# ATSAMD21J17D register map
Vendor: Microchip Technology Inc.; File version: G
CPU: CM0+ r0p1, little endian, no MPU, no FPU, 0x2 interrupt priority bits, 0x0 interrupts
Registers are 32-bit, read-write, reset 0x0 unless marked. A register's access mark holds for its fields unless they carry their own. Offsets are from the block's base; [hi:lo] are bit positions; {n}, {i} and the like mark numbered series; 'fields as' and 'values as' point back to an identical list.

## PORT — Port Module
Base 0x41004400; register names take the prefix PORT_
0x00 DIR0 — Data Direction
  [31:0] DIR — Port Data Direction
0x04 DIRCLR0 — Data Direction Clear
  [31:0] DIRCLR — Port Data Direction Clear
0x08 DIRSET0 — Data Direction Set
  [31:0] DIRSET — Port Data Direction Set
0x0C DIRTGL0 — Data Direction Toggle
  [31:0] DIRTGL — Port Data Direction Toggle
0x10 OUT0 — Data Output Value
  [31:0] OUT — Port Data Output Value
0x14 OUTCLR0 — Data Output Value Clear
  [31:0] OUTCLR — Port Data Output Value Clear
0x18 OUTSET0 — Data Output Value Set
  [31:0] OUTSET — Port Data Output Value Set
0x1C OUTTGL0 — Data Output Value Toggle
  [31:0] OUTTGL — Port Data Output Value Toggle
0x20 IN0 ro — Data Input Value
  [31:0] IN — Port Data Input Value
0x24 CTRL0 — Control
  [31:0] SAMPLING wo — Input Sampling Mode
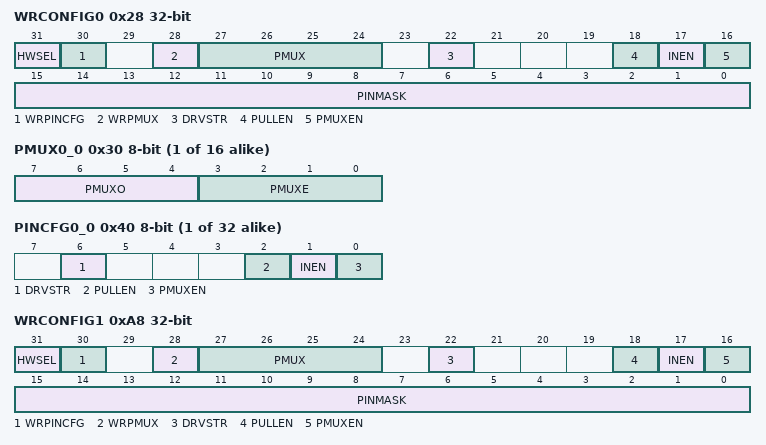
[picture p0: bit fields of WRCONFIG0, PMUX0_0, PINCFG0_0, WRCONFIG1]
0x28 WRCONFIG0 wo — Write Configuration
  [31] HWSEL — Half-Word Select
  [30] WRPINCFG — Write PINCFG
  [28] WRPMUX — Write PMUX
  [27:24] PMUX — Peripheral Multiplexing
  [22] DRVSTR — Output Driver Strength Selection
  [18] PULLEN — Pull Enable
  [17] INEN — Input Enable
  [16] PMUXEN — Peripheral Multiplexer Enable
  [15:0] PINMASK — Pin Mask for Multiple Pin Configuration
{0x30+i} PMUX0_{i} 8-bit (i=0..15) — Peripheral Multiplexing n - Group 0
  [7:4] PMUXO — Peripheral Multiplexing Odd
    0=A (Peripheral function A selected); 1=B (Peripheral function B selected); 2=C (Peripheral function C selected); 3=D (Peripheral function D selected); 4=E (Peripheral function E selected); 5=F (Peripheral function F selected); 6=G (Peripheral function G selected); 7=H (Peripheral function H selected)
  [3:0] PMUXE — Peripheral Multiplexing Even
    values as PMUXO
{0x40+i} PINCFG0_{i} 8-bit (i=0..31) — Pin Configuration n - Group 0
  [6] DRVSTR wo — Output Driver Strength Selection
  [2] PULLEN — Pull Enable
  [1] INEN — Input Enable
  [0] PMUXEN — Peripheral Multiplexer Enable
0x80 DIR1 — Data Direction
  [31:0] DIR — Port Data Direction
0x84 DIRCLR1 — Data Direction Clear
  [31:0] DIRCLR — Port Data Direction Clear
0x88 DIRSET1 — Data Direction Set
  [31:0] DIRSET — Port Data Direction Set
0x8C DIRTGL1 — Data Direction Toggle
  [31:0] DIRTGL — Port Data Direction Toggle
0x90 OUT1 — Data Output Value
  [31:0] OUT — Port Data Output Value
0x94 OUTCLR1 — Data Output Value Clear
  [31:0] OUTCLR — Port Data Output Value Clear
0x98 OUTSET1 — Data Output Value Set
  [31:0] OUTSET — Port Data Output Value Set
0x9C OUTTGL1 — Data Output Value Toggle
  [31:0] OUTTGL — Port Data Output Value Toggle
0xA0 IN1 ro — Data Input Value
  [31:0] IN — Port Data Input Value
0xA4 CTRL1 — Control
  [31:0] SAMPLING wo — Input Sampling Mode
0xA8 WRCONFIG1 wo — Write Configuration
  fields as WRCONFIG0
{0xB0+i} PMUX1_{i} (i=0..15) — Peripheral Multiplexing n - Group 1
{0xC0+i} PINCFG1_{i} (i=0..31) — Pin Configuration n - Group 1

## RTC — Real-Time Counter
Base 0x40001400; register names take the prefix RTC_

## SERCOM0 — Serial Communication Interface 0
Base 0x42000800; register names take the prefix SERCOM_

## SERCOM1 — Serial Communication Interface 1
Base 0x42000C00; register names take the prefix SERCOM_

## SERCOM2 — Serial Communication Interface 2
Base 0x42001000; register names take the prefix SERCOM_

## SERCOM3 — Serial Communication Interface 3
Base 0x42001400; register names take the prefix SERCOM_

## SERCOM4 — Serial Communication Interface 4
Base 0x42001800; register names take the prefix SERCOM_

## SERCOM5 — Serial Communication Interface 5
Base 0x42001C00; register names take the prefix SERCOM_

## TC3 — Basic Timer Counter 3
Base 0x42002C00; register names take the prefix TC_

## TC4 — Basic Timer Counter 4
Base 0x42003000; register names take the prefix TC_

## TC5 — Basic Timer Counter 5
Base 0x42003400; register names take the prefix TC_

## TC6 — Basic Timer Counter 6
Base 0x42003800; register names take the prefix TC_

## TC7 — Basic Timer Counter 7
Base 0x42003C00; register names take the prefix TC_

## USB — Universal Serial Bus
Base 0x41005000; register names take the prefix USB_

## WDT — Watchdog Timer
Base 0x40001000; register names take the prefix WDT_
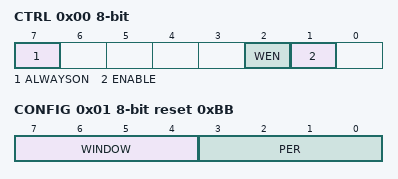
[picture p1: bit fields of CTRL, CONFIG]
0x00 CTRL 8-bit — Control
  [7] ALWAYSON
  [2] WEN — Watchdog Timer Window Mode Enable
  [1] ENABLE
0x01 CONFIG 8-bit reset 0xBB — Configuration
  [7:4] WINDOW — Window Mode Time-Out Period
    0=8 clock cycles; 1=16 clock cycles; 2=32 clock cycles; 3=64 clock cycles; 4=128 clock cycles; 5=256 clock cycles; 6=512 clock cycles; 7=1K (1024 clock cycles); 8=2K (2048 clock cycles); 9=4K (4096 clock cycles); 10=8K (8192 clock cycles); 11=16K (16384 clock cycles)
  [3:0] PER — Time-Out Period
    values as WINDOW
0x02 EWCTRL 8-bit reset 0xB — Early Warning Interrupt Control
  [3:0] EWOFFSET — Early Warning Interrupt Time Offset
    values as CONFIG.WINDOW
0x04 INTENCLR 8-bit — Interrupt Enable Clear
  [0] EW — Early Warning Interrupt Enable
0x05 INTENSET 8-bit — Interrupt Enable Set
  [0] EW — Early Warning Interrupt Enable
0x06 INTFLAG 8-bit — Interrupt Flag Status and Clear
  [0] EW — Early Warning
0x07 STATUS 8-bit ro
  [7] SYNCBUSY — Synchronization Busy
0x08 CLEAR 8-bit wo
  [7:0] CLEAR — Watchdog Clear
    165=KEY (Clear Key)
